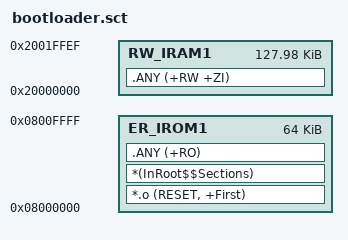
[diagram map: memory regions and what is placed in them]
LR_IROM1 0x08000000 0x00010000  {    ; 64 KB Boot
  ER_IROM1 0x08000000 0x00010000  {
    *.o (RESET, +First)
    *(InRoot$$Sections)
    .ANY (+RO)
  }
  RW_IRAM1 0x20000000 0x0001FFF0  {    ; 128 K - 16 B
    .ANY (+RW +ZI)
  }
}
